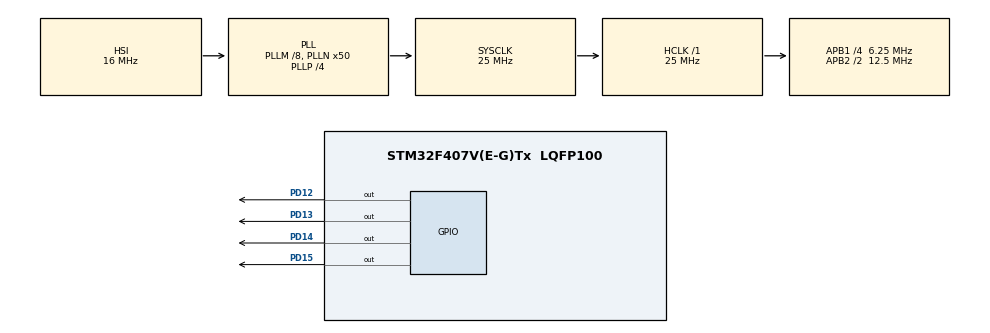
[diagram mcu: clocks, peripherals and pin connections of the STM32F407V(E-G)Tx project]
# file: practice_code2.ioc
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Mcu.Family=STM32F4
RCC.CortexFreq_Value=25000000
NVIC.TIM6_DAC_IRQn=true\:0\:0\:false\:false\:true\:true\:true
TIM6.Prescaler=12499
VP_TIM6_VS_ClockSourceINT.Mode=Enable_Timer
RCC.APB1CLKDivider=RCC_HCLK_DIV4
RCC.SYSCLKSource=RCC_SYSCLKSOURCE_PLLCLK
ProjectManager.StackSize=0x400
PD13.Signal=GPIO_Output
ProjectManager.TargetToolchain=STM32CubeIDE
RCC.HCLKFreq_Value=25000000
RCC.APB2TimFreq_Value=25000000
RCC.LSE_VALUE=32768
RCC.AHBFreq_Value=25000000
RCC.HSE_VALUE=8000000
board=STM32F407G-DISC1
RCC.VCOOutputFreq_Value=100000000
RCC.APB2Freq_Value=12500000
PD13.GPIO_PuPd=GPIO_NOPULL
PD14.GPIO_PuPd=GPIO_NOPULL
TIM6.Period=9999
Mcu.Name=STM32F407V(E-G)Tx
PD14.Signal=GPIO_Output
RCC.48MHZClocksFreq_Value=14285714.285714285
RCC.SYSCLKFreq_VALUE=25000000
Mcu.Package=LQFP100
PD12.Signal=GPIO_Output
PD15.GPIO_PuPd=GPIO_NOPULL
ProjectManager.HeapSize=0x200
RCC.HSI_VALUE=16000000
RCC.PLLP=RCC_PLLP_DIV4
RCC.PLLQ=7
NVIC.PriorityGroup=NVIC_PRIORITYGROUP_0
RCC.APB2CLKDivider=RCC_HCLK_DIV2
RCC.PLLM=8
RCC.PLLN=50
RCC.APB1TimFreq_Value=12500000
RCC.APB1Freq_Value=6250000
PD15.Signal=GPIO_Output
PD12.GPIO_PuPd=GPIO_NOPULL

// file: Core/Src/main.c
/* USER CODE BEGIN Header */
/**
  ******************************************************************************
  * @file           : main.c
  * @brief          : Main program body
  ******************************************************************************
  * @attention
  *
  * <h2><center>&copy; Copyright (c) 2022 STMicroelectronics.
  * All rights reserved.</center></h2>
  *
  * This software component is licensed by ST under BSD 3-Clause license,
  * the "License"; You may not use this file except in compliance with the
  * License. You may obtain a copy of the License at:
  *                        opensource.org/licenses/BSD-3-Clause
  *
  ******************************************************************************
  */
/* USER CODE END Header */
#include "main.h"

TIM_HandleTypeDef htim6;

void SystemClock_Config(void);
static void MX_GPIO_Init(void);
static void MX_TIM6_Init(void);

int main(void)
{

  /* MCU Configuration--------------------------------------------------------*/

  /* Reset of all peripherals, Initializes the Flash interface and the Systick. */
  HAL_Init();

  /* Configure the system clock */
  SystemClock_Config();

  /* Initialize all configured peripherals */
  MX_GPIO_Init();
  MX_TIM6_Init();
  /* USER CODE BEGIN 2 */
HAL_TIM_Base_Start_IT(&htim6);
  /* USER CODE END 2 */

  /* Infinite loop */
  while (1)
  {

  }
}

void SystemClock_Config(void)
{
  RCC_OscInitTypeDef RCC_OscInitStruct = {0};
  RCC_ClkInitTypeDef RCC_ClkInitStruct = {0};

  /** Configure the main internal regulator output voltage
  */
  __HAL_RCC_PWR_CLK_ENABLE();
  __HAL_PWR_VOLTAGESCALING_CONFIG(PWR_REGULATOR_VOLTAGE_SCALE1);
  /** Initializes the RCC Oscillators according to the specified parameters
  * in the RCC_OscInitTypeDef structure.
  */
  RCC_OscInitStruct.OscillatorType = RCC_OSCILLATORTYPE_HSI;
  RCC_OscInitStruct.HSIState = RCC_HSI_ON;
  RCC_OscInitStruct.HSICalibrationValue = RCC_HSICALIBRATION_DEFAULT;
  RCC_OscInitStruct.PLL.PLLState = RCC_PLL_ON;
  RCC_OscInitStruct.PLL.PLLSource = RCC_PLLSOURCE_HSI;
  RCC_OscInitStruct.PLL.PLLM = 8;
  RCC_OscInitStruct.PLL.PLLN = 50;
  RCC_OscInitStruct.PLL.PLLP = RCC_PLLP_DIV4;
  RCC_OscInitStruct.PLL.PLLQ = 7;
  if (HAL_RCC_OscConfig(&RCC_OscInitStruct) != HAL_OK)
  {
    Error_Handler();
  }
  /** Initializes the CPU, AHB and APB buses clocks
  */
  RCC_ClkInitStruct.ClockType = RCC_CLOCKTYPE_HCLK|RCC_CLOCKTYPE_SYSCLK
                              |RCC_CLOCKTYPE_PCLK1|RCC_CLOCKTYPE_PCLK2;
  RCC_ClkInitStruct.SYSCLKSource = RCC_SYSCLKSOURCE_PLLCLK;
  RCC_ClkInitStruct.AHBCLKDivider = RCC_SYSCLK_DIV1;
  RCC_ClkInitStruct.APB1CLKDivider = RCC_HCLK_DIV4;
  RCC_ClkInitStruct.APB2CLKDivider = RCC_HCLK_DIV2;

  if (HAL_RCC_ClockConfig(&RCC_ClkInitStruct, FLASH_LATENCY_0) != HAL_OK)
  {
    Error_Handler();
  }
}

static void MX_TIM6_Init(void)
{

  TIM_MasterConfigTypeDef sMasterConfig = {0};

  htim6.Instance = TIM6;
  htim6.Init.Prescaler = 12499;
  htim6.Init.CounterMode = TIM_COUNTERMODE_UP;
  htim6.Init.Period = 9999;
  htim6.Init.AutoReloadPreload = TIM_AUTORELOAD_PRELOAD_DISABLE;
  if (HAL_TIM_Base_Init(&htim6) != HAL_OK)
  {
    Error_Handler();
  }
  sMasterConfig.MasterOutputTrigger = TIM_TRGO_RESET;
  sMasterConfig.MasterSlaveMode = TIM_MASTERSLAVEMODE_DISABLE;
  if (HAL_TIMEx_MasterConfigSynchronization(&htim6, &sMasterConfig) != HAL_OK)
  {
    Error_Handler();
  }

}

static void MX_GPIO_Init(void)
{
  GPIO_InitTypeDef GPIO_InitStruct = {0};

  /* GPIO Ports Clock Enable */
  __HAL_RCC_GPIOD_CLK_ENABLE();

  /*Configure GPIO pin Output Level */
  HAL_GPIO_WritePin(GPIOD, GPIO_PIN_12|GPIO_PIN_13|GPIO_PIN_14|GPIO_PIN_15, GPIO_PIN_RESET);

  /*Configure GPIO pins : PD12 PD13 PD14 PD15 */
  GPIO_InitStruct.Pin = GPIO_PIN_12|GPIO_PIN_13|GPIO_PIN_14|GPIO_PIN_15;
  GPIO_InitStruct.Mode = GPIO_MODE_OUTPUT_PP;
  GPIO_InitStruct.Pull = GPIO_NOPULL;
  GPIO_InitStruct.Speed = GPIO_SPEED_FREQ_LOW;
  HAL_GPIO_Init(GPIOD, &GPIO_InitStruct);

}

/* USER CODE BEGIN 4 */

void HAL_TIM_PeriodElapsedCallback(TIM_HandleTypeDef *htim)
{
	if(htim == &htim6)
	{
		HAL_GPIO_WritePin(GPIOD, GPIO_PIN_14, GPIO_PIN_SET);
	}

}

/* USER CODE END 4 */

void Error_Handler(void)
{
  __disable_irq();
  while (1)
  {
  }
}

/************************ (C) COPYRIGHT STMicroelectronics *****END OF FILE****/
